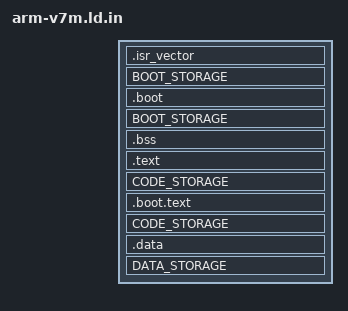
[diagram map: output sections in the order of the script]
/*
 * Copyright (C) 2014-2015 Fabien Parent. All rights reserved.
 * Author: Fabien Parent <parent.f@gmail.com>
 *
 * Provided under the three clause BSD license found in the LICENSE file.
 */

#include <asm/linker-utils.h>

ENTRY(reset_handler)
SECTIONS
{
    .isr_vector : {
        KEEP(*(.isr_vector))
    } BOOT_STORAGE

    // Align on 32 bytes in order to give room for a small mpu region
    // at address 0 that can be used to avoid NULL pointer deference
    .boot ALIGN(32): {
        KEEP(*(.boot))
    } BOOT_STORAGE

    .bss : {
        _bss = .;
        *(.bss)
        _ebss = .;
    } > SRAM

    .text : {
        *(.text)
        *(.text.*)
        *(.rodata*)
    } CODE_STORAGE

    _text_lma = LOADADDR(.text);
    _text_vma = ADDR(.text);
    _text_size = SIZEOF(.text);

    .boot.text : {
        *(.boot.text)
    } CODE_STORAGE

    _boot_text_lma = LOADADDR(.boot.text);
    _boot_text_vma = ADDR(.boot.text);
    _boot_text_size = SIZEOF(.boot.text);

    .data : {
        *(.data)
        *(.data.*)
    } DATA_STORAGE

    _data_lma = LOADADDR(.data);
    _data_vma = ADDR(.data);
    _data_size = SIZEOF(.data);

    _bor = ORIGIN(SRAM);
    _eor = ORIGIN(SRAM) + LENGTH(SRAM);

    /DISCARD/ : {
        *(.ARM.exidx*)
    }
}
